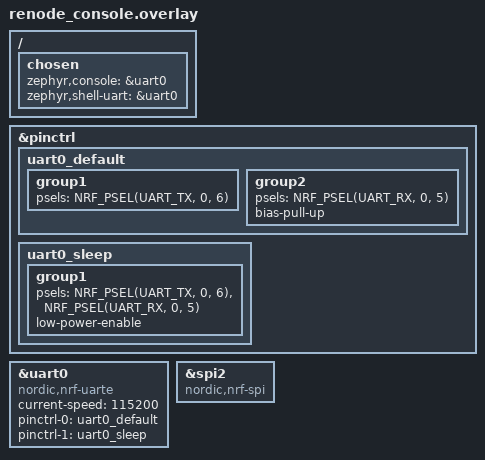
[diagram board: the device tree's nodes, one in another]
/*
 * SPDX-License-Identifier: GPL-3.0-or-later
 * SPDX-FileCopyrightText: The contributors to the LICHEN project
 *
 * Renode console overlay for Seeed T1000-E.
 *
 * The physical T1000-E uses USB CDC-ACM (cdc_acm_uart0) for console, which
 * Renode cannot capture headlessly. This overlay routes the Zephyr console
 * and shell to UARTE0 (0x40002000), which Renode's nrf52840 platform models
 * and exposes via `showAnalyzer uart0` / a file backend.
 *
 * Pin assignments are arbitrary (Renode does not enforce pinctrl routing)
 * but valid psels are required for the Zephyr build to configure the node.
 * Uses pins that do not conflict with T1000-E's SPI2 (LR1110) or UART1 (GNSS).
 *
 * Usage:
 *   west build -b t1000_e/nrf52840 lichen/apps/puck -- \
 *     -DEXTRA_DTC_OVERLAY_FILE=lichen/boards/renode/t1000_e/support/renode_console.overlay \
 *     -DEXTRA_CONF_FILE=lichen/boards/renode/t1000_e/support/renode_console.conf
 */

&pinctrl {
	uart0_default: uart0_default {
		group1 {
			psels = <NRF_PSEL(UART_TX, 0, 6)>;
		};
		group2 {
			psels = <NRF_PSEL(UART_RX, 0, 5)>;
			bias-pull-up;
		};
	};

	uart0_sleep: uart0_sleep {
		group1 {
			psels = <NRF_PSEL(UART_TX, 0, 6)>,
				<NRF_PSEL(UART_RX, 0, 5)>;
			low-power-enable;
		};
	};
};

&uart0 {
	compatible = "nordic,nrf-uarte";
	status = "okay";
	current-speed = <115200>;
	pinctrl-0 = <&uart0_default>;
	pinctrl-1 = <&uart0_sleep>;
	pinctrl-names = "default", "sleep";
};

/* Renode 1.16.1 does not model the SPIM STOP task/event used by nrfx. */
&spi2 {
	compatible = "nordic,nrf-spi";
};

/ {
	chosen {
		zephyr,console = &uart0;
		zephyr,shell-uart = &uart0;
	};
};
